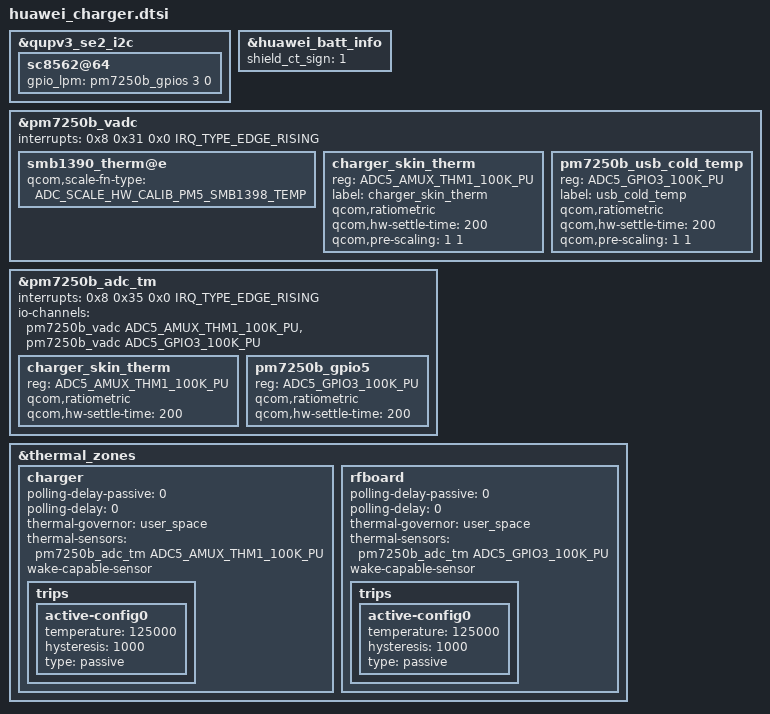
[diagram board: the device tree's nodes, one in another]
#include <dt-bindings/iio/qcom,spmi-vadc.h>
&qupv3_se2_i2c {
	status = "ok";
	sc8562@64{
		gpio_lpm = <&pm7250b_gpios 3 0>;
	};
};

&huawei_batt_info {
    shield_ct_sign = <1>;
};

&pm7250b_vadc {
	interrupts = <0x8 0x31 0x0 IRQ_TYPE_EDGE_RISING>;

	smb1390_therm@e {
		qcom,scale-fn-type = <ADC_SCALE_HW_CALIB_PM5_SMB1398_TEMP>;
	};

	charger_skin_therm {
		reg = <ADC5_AMUX_THM1_100K_PU>;
		label = "charger_skin_therm";
		qcom,ratiometric;
		qcom,hw-settle-time = <200>;
		qcom,pre-scaling = <1 1>;
	};

	pm7250b_usb_cold_temp {
		reg = <ADC5_GPIO3_100K_PU>;
		label = "usb_cold_temp";
		qcom,ratiometric;
		qcom,hw-settle-time = <200>;
		qcom,pre-scaling = <1 1>;
	};
};

&pm7250b_adc_tm {
	interrupts = <0x8 0x35 0x0 IRQ_TYPE_EDGE_RISING>;

	io-channels = <&pm7250b_vadc ADC5_AMUX_THM1_100K_PU>,
             <&pm7250b_vadc ADC5_GPIO3_100K_PU>;

	charger_skin_therm {
		reg = <ADC5_AMUX_THM1_100K_PU>;
		qcom,ratiometric;
		qcom,hw-settle-time = <200>;
	};

	pm7250b_gpio5 {
		reg = <ADC5_GPIO3_100K_PU>;
		qcom,ratiometric;
		qcom,hw-settle-time = <200>;
	};
};

&thermal_zones {

	charger {
		polling-delay-passive = <0>;
		polling-delay = <0>;
		thermal-governor = "user_space";
		thermal-sensors = <&pm7250b_adc_tm ADC5_AMUX_THM1_100K_PU>;
		wake-capable-sensor;
		trips {
			active-config0 {
				temperature = <125000>;
				hysteresis = <1000>;
				type = "passive";
			};
		};
	};

	rfboard {
		polling-delay-passive = <0>;
		polling-delay = <0>;
		thermal-governor = "user_space";
		thermal-sensors = <&pm7250b_adc_tm ADC5_GPIO3_100K_PU>;
		wake-capable-sensor;
		trips {
			active-config0 {
				temperature = <125000>;
				hysteresis = <1000>;
				type = "passive";
			};
		};
	};
};
